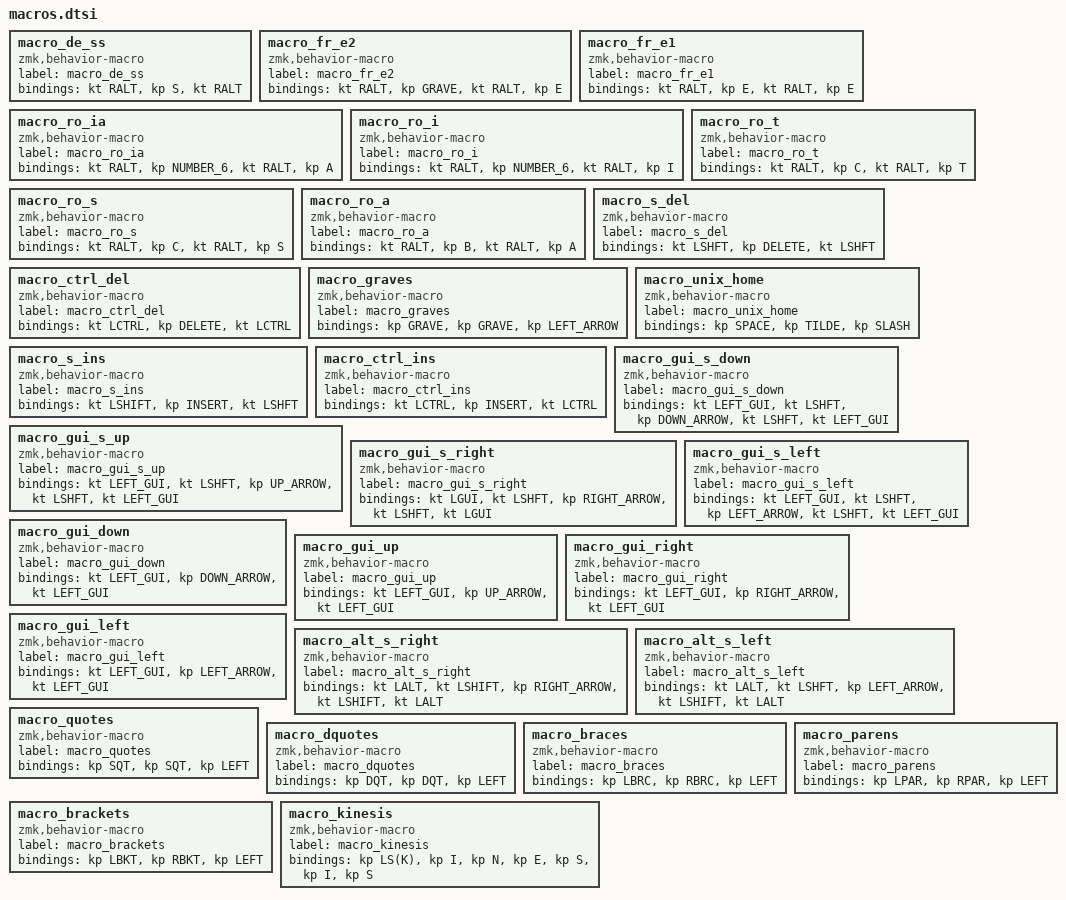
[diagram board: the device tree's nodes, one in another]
macro_de_ss: macro_de_ss{
compatible = "zmk,behavior-macro";
label = "macro_de_ss";
#binding-cells = <0>;
bindings = <&kt RALT>, <&kp S>, <&kt RALT>;
};
macro_fr_e2: macro_fr_e2{
compatible = "zmk,behavior-macro";
label = "macro_fr_e2";
#binding-cells = <0>;
bindings = <&kt RALT>, <&kp GRAVE>, <&kt RALT>, <&kp E>;
};
macro_fr_e1: macro_fr_e1{
compatible = "zmk,behavior-macro";
label = "macro_fr_e1";
#binding-cells = <0>;
bindings = <&kt RALT>, <&kp E>, <&kt RALT>, <&kp E>;
};
macro_ro_ia: macro_ro_ia{
compatible = "zmk,behavior-macro";
label = "macro_ro_ia";
#binding-cells = <0>;
bindings = <&kt RALT>, <&kp NUMBER_6>, <&kt RALT>, <&kp A>;
};
macro_ro_i: macro_ro_i{
compatible = "zmk,behavior-macro";
label = "macro_ro_i";
#binding-cells = <0>;
bindings = <&kt RALT>, <&kp NUMBER_6>, <&kt RALT>, <&kp I>;
};
macro_ro_t: macro_ro_t{
compatible = "zmk,behavior-macro";
label = "macro_ro_t";
#binding-cells = <0>;
bindings = <&kt RALT>, <&kp C>, <&kt RALT>, <&kp T>;
};
macro_ro_s: macro_ro_s{
compatible = "zmk,behavior-macro";
label = "macro_ro_s";
#binding-cells = <0>;
bindings = <&kt RALT>, <&kp C>, <&kt RALT>, <&kp S>;
};
macro_ro_a: macro_ro_a{
compatible = "zmk,behavior-macro";
label = "macro_ro_a";
#binding-cells = <0>;
bindings = <&kt RALT>, <&kp B>, <&kt RALT>, <&kp A>;
};
macro_s_del: macro_s_del{
compatible = "zmk,behavior-macro";
label = "macro_s_del";
#binding-cells = <0>;
bindings = <&kt LSHFT>, <&kp DELETE>, <&kt LSHFT>;
};
macro_ctrl_del: macro_ctrl_del{
compatible = "zmk,behavior-macro";
label = "macro_ctrl_del";
#binding-cells = <0>;
bindings = <&kt LCTRL>, <&kp DELETE>, <&kt LCTRL>;
};
macro_graves: macro_graves{
compatible = "zmk,behavior-macro";
label = "macro_graves";
#binding-cells = <0>;
bindings = <&kp GRAVE>, <&kp GRAVE>, <&kp LEFT_ARROW>;
};
macro_unix_home: macro_unix_home{
compatible = "zmk,behavior-macro";
label = "macro_unix_home";
#binding-cells = <0>;
bindings = <&kp SPACE>, <&kp TILDE>, <&kp SLASH>;
};
macro_s_ins: macro_s_ins{
compatible = "zmk,behavior-macro";
label = "macro_s_ins";
#binding-cells = <0>;
bindings = <&kt LSHIFT>, <&kp INSERT>, <&kt LSHFT>;
};
macro_ctrl_ins: macro_ctrl_ins{
compatible = "zmk,behavior-macro";
label = "macro_ctrl_ins";
#binding-cells = <0>;
bindings = <&kt LCTRL>, <&kp INSERT>, <&kt LCTRL>;
};
macro_gui_s_down: macro_gui_s_down{
compatible = "zmk,behavior-macro";
label = "macro_gui_s_down";
#binding-cells = <0>;
bindings = <&kt LEFT_GUI>, <&kt LSHFT>, <&kp DOWN_ARROW>, <&kt LSHFT>, <&kt LEFT_GUI>;
};
macro_gui_s_up: macro_gui_s_up{
compatible = "zmk,behavior-macro";
label = "macro_gui_s_up";
#binding-cells = <0>;
bindings = <&kt LEFT_GUI>, <&kt LSHFT>, <&kp UP_ARROW>, <&kt LSHFT>, <&kt LEFT_GUI>;
};
macro_gui_s_right: macro_gui_s_right{
compatible = "zmk,behavior-macro";
label = "macro_gui_s_right";
#binding-cells = <0>;
bindings = <&kt LGUI>, <&kt LSHFT>, <&kp RIGHT_ARROW>, <&kt LSHFT>, <&kt LGUI>;
};
macro_gui_s_left: macro_gui_s_left{
compatible = "zmk,behavior-macro";
label = "macro_gui_s_left";
#binding-cells = <0>;
bindings = <&kt LEFT_GUI>, <&kt LSHFT>, <&kp LEFT_ARROW>, <&kt LSHFT>, <&kt LEFT_GUI>;
};
macro_gui_down: macro_gui_down{
compatible = "zmk,behavior-macro";
label = "macro_gui_down";
#binding-cells = <0>;
bindings = <&kt LEFT_GUI>, <&kp DOWN_ARROW>, <&kt LEFT_GUI>;
};
macro_gui_up: macro_gui_up{
compatible = "zmk,behavior-macro";
label = "macro_gui_up";
#binding-cells = <0>;
bindings = <&kt LEFT_GUI>, <&kp UP_ARROW>, <&kt LEFT_GUI>;
};
macro_gui_right: macro_gui_right{
compatible = "zmk,behavior-macro";
label = "macro_gui_right";
#binding-cells = <0>;
bindings = <&kt LEFT_GUI>, <&kp RIGHT_ARROW>, <&kt LEFT_GUI>;
};
macro_gui_left: macro_gui_left{
compatible = "zmk,behavior-macro";
label = "macro_gui_left";
#binding-cells = <0>;
bindings = <&kt LEFT_GUI>, <&kp LEFT_ARROW>, <&kt LEFT_GUI>;
};
macro_alt_s_right: macro_alt_s_right{
compatible = "zmk,behavior-macro";
label = "macro_alt_s_right";
#binding-cells = <0>;
bindings = <&kt LALT>, <&kt LSHIFT>, <&kp RIGHT_ARROW>, <&kt LSHIFT>, <&kt LALT>;
};
macro_alt_s_left: macro_alt_s_left{
compatible = "zmk,behavior-macro";
label = "macro_alt_s_left";
#binding-cells = <0>;
bindings = <&kt LALT>, <&kt LSHFT>, <&kp LEFT_ARROW>, <&kt LSHIFT>, <&kt LALT>;
};
macro_quotes: macro_quotes{
compatible = "zmk,behavior-macro";
label = "macro_quotes";
#binding-cells = <0>;
bindings = <&kp SQT>, <&kp SQT>, <&kp LEFT>;
};
macro_dquotes: macro_dquotes{
compatible = "zmk,behavior-macro";
label = "macro_dquotes";
#binding-cells = <0>;
bindings = <&kp DQT>, <&kp DQT>, <&kp LEFT>;
};
macro_braces: macro_braces{
compatible = "zmk,behavior-macro";
label = "macro_braces";
#binding-cells = <0>;
bindings = <&kp LBRC>, <&kp RBRC>, <&kp LEFT>;
};
macro_parens: macro_parens{
compatible = "zmk,behavior-macro";
label = "macro_parens";
#binding-cells = <0>;
bindings = <&kp LPAR>, <&kp RPAR>, <&kp LEFT>;
};
macro_brackets: macro_brackets{
compatible = "zmk,behavior-macro";
label = "macro_brackets";
#binding-cells = <0>;
bindings = <&kp LBKT>, <&kp RBKT>, <&kp LEFT>;
};
macro_kinesis: macro_kinesis{
compatible = "zmk,behavior-macro";
label = "macro_kinesis";
#binding-cells = <0>;
bindings = <&kp LS(K)>, <&kp I>, <&kp N>, <&kp E>, <&kp S>, <&kp I>, <&kp S>;
};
